# AltaRiscv register map
File version: 1.0
Registers are 32-bit, read-write, reset 0x0 unless marked. A register's access mark holds for its fields unless they carry their own. Offsets are from the block's base; [hi:lo] are bit positions; {n}, {i} and the like mark numbered series; 'fields as' and 'values as' point back to an identical list.

## USB0 — USB registers
Base 0x41001000
0x80 GPTIMER0LD — General Purpose Timer #0 Load Register
  [23:0] GPTIMER0LD
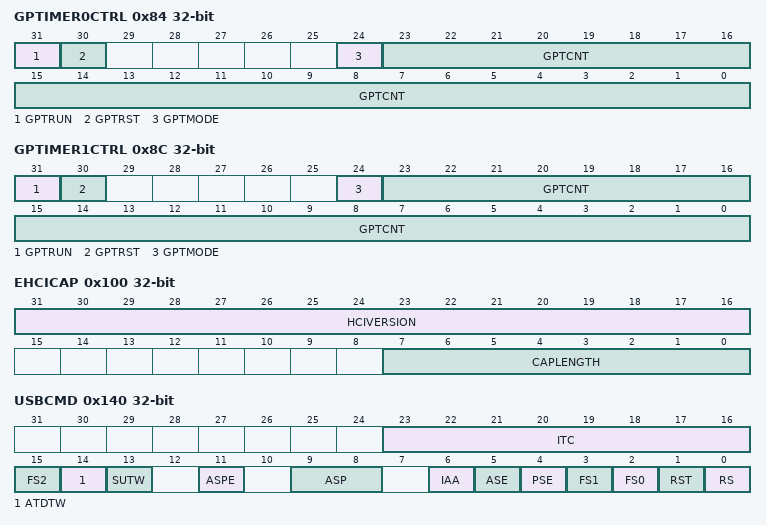
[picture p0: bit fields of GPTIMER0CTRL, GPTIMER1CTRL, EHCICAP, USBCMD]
0x84 GPTIMER0CTRL access per field — General Purpose Timer #0 Control Register
  [31] GPTRUN rw — Timer Run
  [30] GPTRST rw — Timer Reset
  [24] GPTMODE rw — Timer Mode
    0=One shot; 1=Repeat
  [23:0] GPTCNT ro — Timer Counter
0x88 GPTIMER1LD — General Purpose Timer #1 Load Register
  [23:0] GPTIMER1LD
0x8C GPTIMER1CTRL access per field — General Purpose Timer #1 Control Register
  fields as GPTIMER0CTRL
0x100 EHCICAP ro — ECHI Capability register
  [31:16] HCIVERSION — Host Interface Version Number
  [7:0] CAPLENGTH — Capability Register Length
0x104 HCSPARAMS ro — Host Controller Structural Parameters
0x108 HCCPARAMS ro — Host Controller Capability Parameters
0x140 USBCMD — USB Command
  [23:16] ITC — Interrupt Threshold Control
  [15] FS2 — Frame List Size Bit 2
  [14] ATDTW — Add dTD TripWire
  [13] SUTW — Setup TripWire
  [11] ASPE — Asynchronous Schedule Park Mode Enable
  [9:8] ASP — Asynchronous Schedule Park Mode Count
  [6] IAA — Interrupt on Async Advance Doorbell
  [5] ASE — Asynchronous Schedule Enable
  [4] PSE — Periodic Schedule Enable
  [3] FS1 — Frame List Size Bit 1
  [2] FS0 — Frame List Size Bit 0
  [1] RST — Controller Reset
  [0] RS — Run/Stop
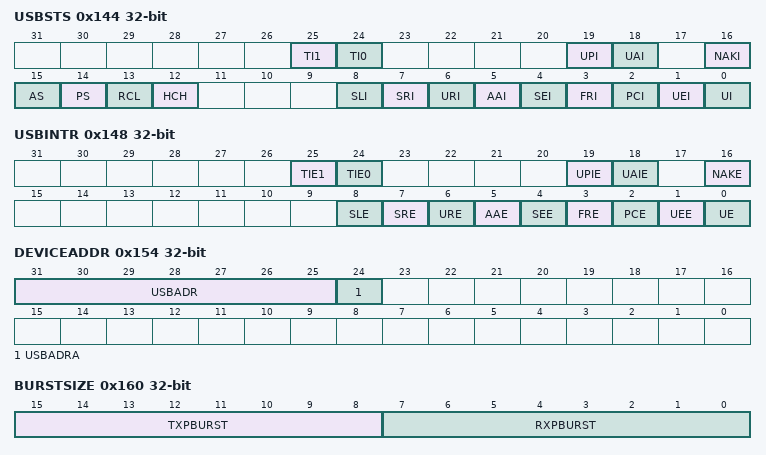
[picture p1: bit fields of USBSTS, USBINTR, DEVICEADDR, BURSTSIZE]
0x144 USBSTS access per field — USB Status
  [25] TI1 rw — General Purpose Timer Interrupt 1
  [24] TI0 rw — General Purpose Timer Interrupt 0
  [19] UPI rw — USB Host Periodic Interrupt
  [18] UAI rw — USB Host Asynchronous Interrupt
  [16] NAKI ro — NAK Interrupt
  [15] AS ro — Asynchronous Schedule Status
  [14] PS ro — Periodic Schedule Status
  [13] RCL ro — Reclamation
  [12] HCH ro — HCHalted
  [8] SLI rw — DCSuspend
  [7] SRI rw — SOF Received
  [6] URI rw — USB Reset Received
  [5] AAI rw — Interrupt on Async Advance
  [4] SEI rw — System Error (from AHB)
  [3] FRI rw — Frame List Rollover
  [2] PCI rw — Port Change Detect
  [1] UEI rw — USB Error Interrupt
  [0] UI rw — USB Interrupt
0x148 USBINTR access per field — USB Interrupt Enable
  [25] TIE1 rw — General Purpose Timer Interrupt Enable 1
  [24] TIE0 rw — General Purpose Timer Interrupt Enable 0
  [19] UPIE rw — USB Host Periodic Interrupt Enable
  [18] UAIE rw — USB Host Asynchronous Interrupt Enable
  [16] NAKE ro — NAK Interrupt Enable
  [8] SLE rw — DCSuspend Interrupt Enable
  [7] SRE rw — SOF Received Interrupt Enable
  [6] URE rw — USB Reset Received Interrupt Enable
  [5] AAE rw — Interrupt on Async Advance Enable
  [4] SEE rw — System Error (from AHB) Interrupt Enable
  [3] FRE rw — Frame List Rollover Interrupt Enable
  [2] PCE rw — Port Change Detect Interrupt Enable
  [1] UEE rw — USB Error Interrupt Enable
  [0] UE rw — USB Interrupt Enable
0x14C FRINDEX — USB Frame Index
  [13:0] FRINDEX
0x154 PERIODICLISTBASE — Frame List Base Address
0x154 DEVICEADDR (alternate view of PERIODICLISTBASE) — Device Address
  [31:25] USBADR — USB Device address
  [24] USBADRA — Device address advance
0x158 ASYNCLISTADDR — Asynchronous List Address / Endpoint List Address
0x160 BURSTSIZE — Programmable Burst Size
  [15:8] TXPBURST — Programmable TX Burst Length
  [7:0] RXPBURST — Programmable RX Burst Length
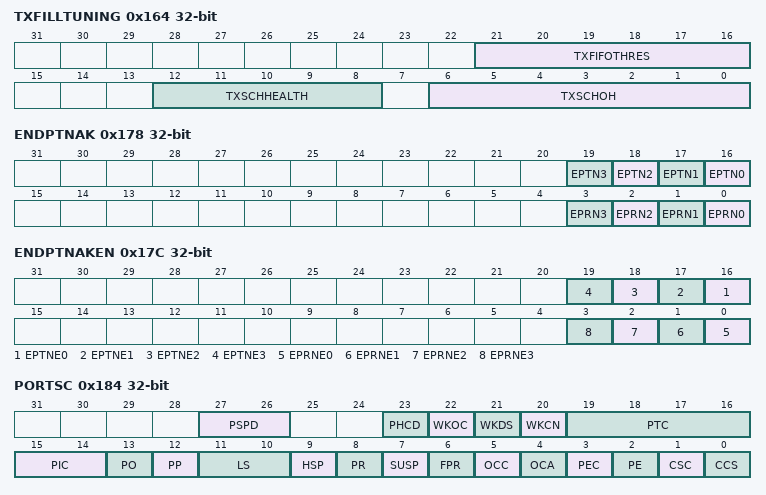
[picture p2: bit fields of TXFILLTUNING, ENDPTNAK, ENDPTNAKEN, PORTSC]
0x164 TXFILLTUNING — Host Transmit Pre-Buffer Packet Tuning
  [21:16] TXFIFOTHRES — FIFO Burst Threshold
  [12:8] TXSCHHEALTH — Scheduler Health Counter
  [6:0] TXSCHOH — Scheduler Overhead
0x178 ENDPTNAK — Endpoint NAK
  [n+16] EPTN{n} (n=0..3) — Endpoing {n} TX NAK
  [n] EPRN{n} (n=0..3) — Endpoing {n} RX NAK
0x17C ENDPTNAKEN — Endpoint NAK Enable
  [n+16] EPTNE{n} (n=0..3) — TX Endpoint {n} NAK Interrupt Enable
  [n] EPRNE{n} (n=0..3) — RX Endpoint {n} NAK Interrupt Enable
0x184 PORTSC access per field — Port Status/Control
  [27:26] PSPD rw — Port Speed
    0=Full Speed; 1=Low Speed; 2=High Speed; 3=Not Connected
  [23] PHCD rw — PHY Low Power Clock Disable
  [22] WKOC rw — Wake on Over-current Enable
  [21] WKDS rw — Wake on Disconnect Enable
  [20] WKCN rw — Wake on Connect Enable
  [19:16] PTC rw — Port Test Control
  [15:14] PIC rw — Port Indicator Control
  [13] PO ro — Port Owner
  [12] PP rw — Port Power
  [11:10] LS ro — Line Status
    0=SE0; 1=J-state; 2=K-state
  [9] HSP ro — High-Speed Port
  [8] PR rw — Port Reset
  [7] SUSP rw — Suspend
  [6] FPR rw — Force Port Resume
  [5] OCC rw — Over-current Change
  [4] OCA ro — Over-current Active
  [3] PEC rw — Port Enabled Change
  [2] PE rw — Port Enabled
  [1] CSC rw — Connect Status Change
  [0] CCS ro — Current Connect Status
    0=No Device; 1=Device Attached
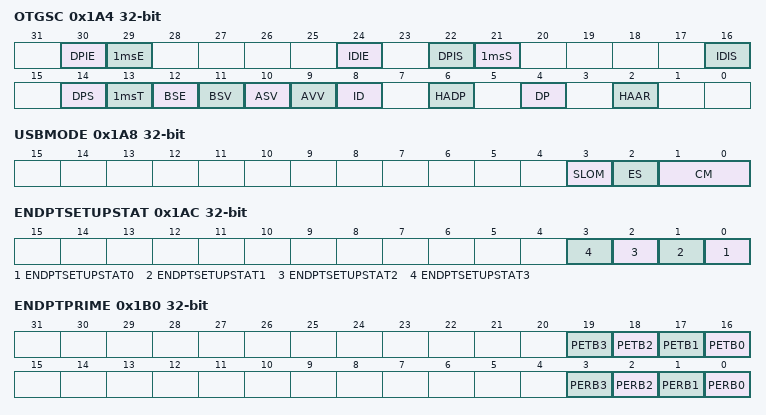
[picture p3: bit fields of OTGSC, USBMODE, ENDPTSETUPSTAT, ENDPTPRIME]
0x1A4 OTGSC access per field — OTG Status and Control
  [30] DPIE rw — Data Pulse Interrupt Enable
  [29] 1msE rw — 1 millisecond timer Interrupt Enable
  [24] IDIE rw — USB ID Interrupt Enable
  [22] DPIS rw — Data Pulse Interrupt Status
  [21] 1msS rw — 1 millisecond timer Interrupt Status
  [16] IDIS rw — USB ID Interrupt Status
  [14] DPS ro — Data Bus Pulsing Status
  [13] 1msT ro — 1 millisecond timer toggle
  [12] BSE ro — B Session End
  [11] BSV ro — B Session Valid
  [10] ASV ro — A Session Valid
  [9] AVV ro — A VBus Valid
  [8] ID ro — USB ID
    0=A-device; 1=B-device
  [6] HADP rw — Hardware Assist Data-Pulse
  [4] DP rw — Data Pulsing
  [2] HAAR rw — Hardware Assist Auto-Reset
0x1A8 USBMODE — USB Device Mode
  [3] SLOM — Setup Lockout Mode
    0=ON; 1=OFF
  [2] ES — Endian Select
    0=LE; 1=BE
  [1:0] CM — Controller Mode
    0=Idle; 2=Device Mode; 3=Host Mode
0x1AC ENDPTSETUPSTAT — Endpoint Setup Status
  [n] ENDPTSETUPSTAT{n} (n=0..3) — Endpoing {n} Setup Status
0x1B0 ENDPTPRIME — Endpoint Initialization
  [n+16] PETB{n} (n=0..3) — Prime Endpoint {n} TX Buffer
  [n] PERB{n} (n=0..3) — Prime Endpoint {n} RX Buffer
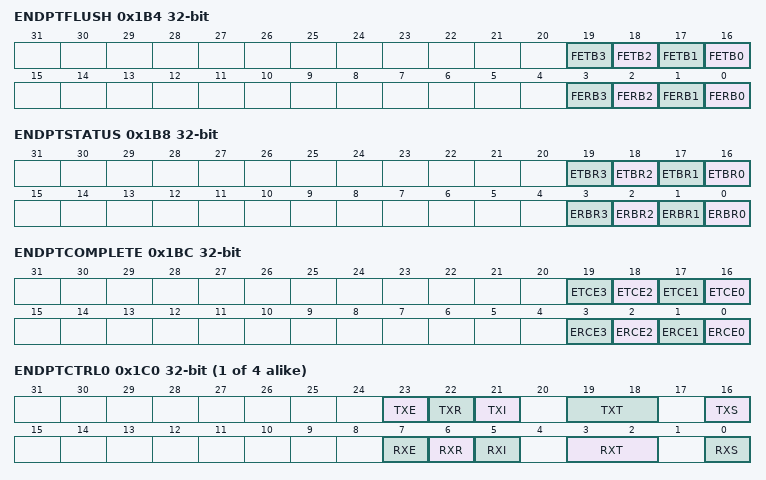
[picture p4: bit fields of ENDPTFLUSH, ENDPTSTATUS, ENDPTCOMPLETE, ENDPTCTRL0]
0x1B4 ENDPTFLUSH — Endpoint De-Initialize
  [n+16] FETB{n} (n=0..3) — Flush Endpoint {n} TX Buffer
  [n] FERB{n} (n=0..3) — Flush Endpoint {n} RX Buffer
0x1B8 ENDPTSTATUS — Endpoint Status
  [n+16] ETBR{n} (n=0..3) — Endpoint {n} TX Buffer Ready
  [n] ERBR{n} (n=0..3) — Endpoint {n} RX Buffer Ready
0x1BC ENDPTCOMPLETE — Endpoint Complete
  [n+16] ETCE{n} (n=0..3) — Endpoint {n} TX Complete Event
  [n] ERCE{n} (n=0..3) — Endpoint {n} RX Complete Event
{0x1C0+4i} ENDPTCTRL{i} (i=0..3) — Endpoint {i} Control
  [23] TXE — TX Endpoint Enable
  [22] TXR — TX Data Toggle Reset
  [21] TXI — TX Data Toggle Inhibit
  [19:18] TXT — TX Endpoint Type
    0=Control; 1=Isochronous; 2=Bulk; 3=Interrupt
  [16] TXS — TX Endpoint Stall
  [7] RXE — RX Endpoint Enable
  [6] RXR — RX Data Toggle Reset
  [5] RXI — RX Data Toggle Inhibit
  [3:2] RXT — RX Endpoint Type
    0=Control; 1=Isochronous; 2=Bulk; 3=Interrupt
  [0] RXS — RX Endpoint Stall
